# PIC32MK0128MCA032 device description
Architecture: MIPS; Family: PIC32MK; Series: PIC32MK
Registers are 32-bit, read-write, no defined reset value unless marked. A register's access mark holds for its fields unless they carry their own. Offsets are from the block's base; [hi:lo] are bit positions; lines under a group give offsets from that group; {n}, {i} and the like mark numbered series.

## INT
Instances: INT 0x1f810000 in periph_pb1_fast
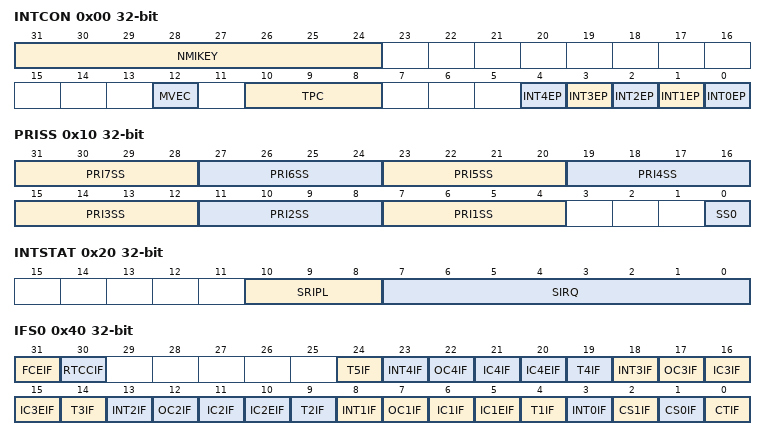
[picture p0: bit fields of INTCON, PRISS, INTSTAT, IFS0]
0x00 INTCON — Interrupt Control Register
  [31:24] NMIKEY
  [12] MVEC — Multi Vector Configuration bit
    1=Interrupt controller configured for multi vectored mode; 0=Interrupt controller configured for single vectored mode
  [10:8] TPC — Interrupt Proximity Timer Control bits
    {v}=Interrupts of group priority {v} or lower start the Interrupt Proximity timer (v=2..7); 1=Interrupts of group priority 1 start the Interrupt Proximity timer; 0=Disables Interrupt Proximity timer
  [n] INT{n}EP (n=0..4) — External Interrupt {n} Edge
    1=Rising edge; 0=Falling edge
0x10 PRISS — Priority Shadow Select Register
  [4n+3:4n] PRI{n}SS (n=1..7) — Interrupt with Priority Level {n} Shadow Set bits
    {v}=Interrupt with a priority level of {n} uses Shadow Set {v} (v=1..7); 0=Interrupt with a priority level of {n} uses Shadow Set 0 (default)
  [0] SS0 — Single Vector Shadow Register Set bit
    1=Single vector is presented with a shadow set; 0=Single vector is not presented with a shadow set
0x20 INTSTAT ro
  [10:8] SRIPL, [7:0] SIRQ
0x30 IPTMR
0x40 IFS0
  [31] FCEIF, [30] RTCCIF, [5n-1] T{n}IF (n=1..5), [5n+3] INT{n}IF (n=0..4), [5n+2] OC{n}IF (n=1..4), [5n+1] IC{n}IF (n=1..4), [5n] IC{n}EIF (n=1..4), [2] CS1IF, [1] CS0IF, [0] CTIF
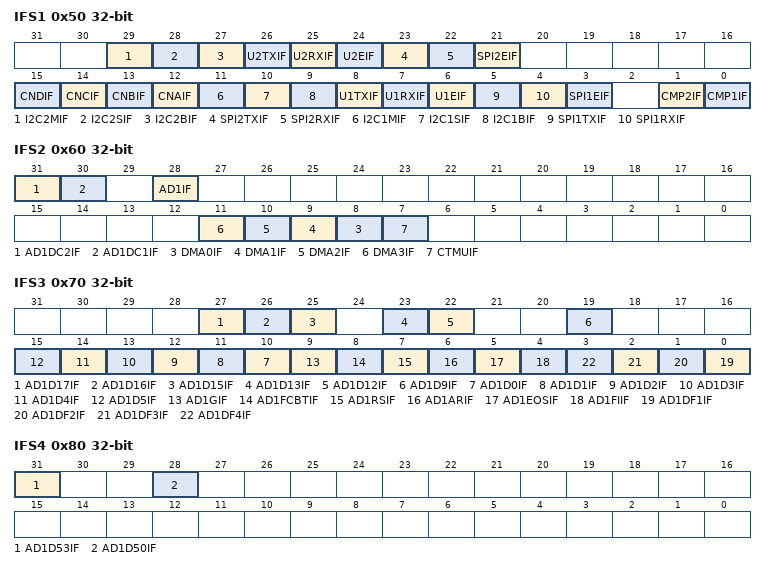
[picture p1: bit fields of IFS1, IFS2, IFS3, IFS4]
0x50 IFS1
  [29] I2C2MIF, [28] I2C2SIF, [27] I2C2BIF, [26] U2TXIF, [25] U2RXIF, [24] U2EIF, [23] SPI2TXIF, [22] SPI2RXIF, [21] SPI2EIF, [15] CNDIF, [14] CNCIF, [13] CNBIF, [12] CNAIF, [11] I2C1MIF, [10] I2C1SIF, [9] I2C1BIF, [8] U1TXIF, [7] U1RXIF, [6] U1EIF, [5] SPI1TXIF, [4] SPI1RXIF, [3] SPI1EIF, [1] CMP2IF, [0] CMP1IF
0x60 IFS2
  [31] AD1DC2IF, [30] AD1DC1IF, [28] AD1IF, [n+8] DMA{n}IF (n=0..3), [7] CTMUIF
0x70 IFS3
  [27] AD1D17IF, [26] AD1D16IF, [25] AD1D15IF, [23] AD1D13IF, [22] AD1D12IF, [19] AD1D9IF, [n+10] AD1D{n}IF (n=0..5), [9] AD1GIF, [8] AD1FCBTIF, [7] AD1RSIF, [6] AD1ARIF, [5] AD1EOSIF, [4] AD1FIIF, [n-1] AD1DF{n}IF (n=1..4)
0x80 IFS4
  [31] AD1D53IF, [28] AD1D50IF
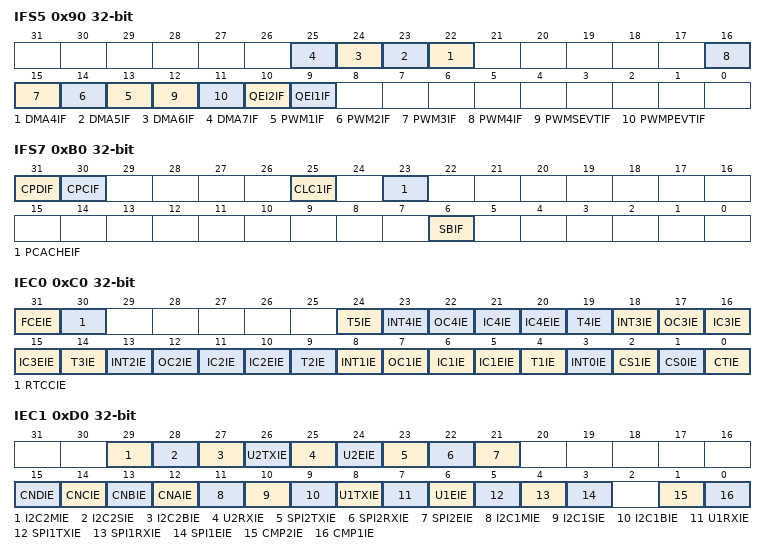
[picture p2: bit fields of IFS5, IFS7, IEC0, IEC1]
0x90 IFS5
  [n+18] DMA{n}IF (n=4..7), [n+12] PWM{n}IF (n=1..4), [12] PWMSEVTIF, [11] PWMPEVTIF, [10] QEI2IF, [9] QEI1IF
0xB0 IFS7
  [31] CPDIF
  [30] CPCIF
  [25] CLC1IF
  [23] PCACHEIF — PCACHE Interrupt Flag
  [6] SBIF
0xC0 IEC0
  [31] FCEIE, [30] RTCCIE, [5n-1] T{n}IE (n=1..5), [5n+3] INT{n}IE (n=0..4), [5n+2] OC{n}IE (n=1..4), [5n+1] IC{n}IE (n=1..4), [5n] IC{n}EIE (n=1..4), [2] CS1IE, [1] CS0IE, [0] CTIE
0xD0 IEC1
  [29] I2C2MIE, [28] I2C2SIE, [27] I2C2BIE, [26] U2TXIE, [25] U2RXIE, [24] U2EIE, [23] SPI2TXIE, [22] SPI2RXIE, [21] SPI2EIE, [15] CNDIE, [14] CNCIE, [13] CNBIE, [12] CNAIE, [11] I2C1MIE, [10] I2C1SIE, [9] I2C1BIE, [8] U1TXIE, [7] U1RXIE, [6] U1EIE, [5] SPI1TXIE, [4] SPI1RXIE, [3] SPI1EIE, [1] CMP2IE, [0] CMP1IE
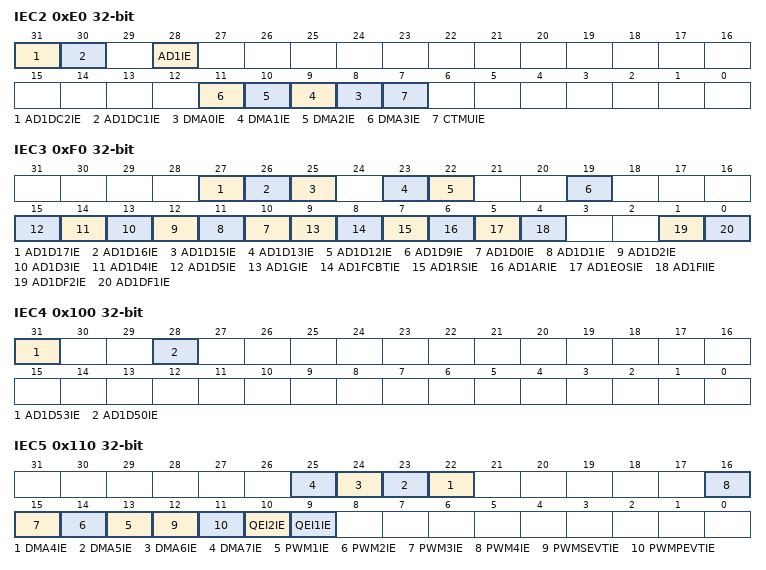
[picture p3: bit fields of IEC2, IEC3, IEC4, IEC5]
0xE0 IEC2
  [31] AD1DC2IE, [30] AD1DC1IE, [28] AD1IE, [n+8] DMA{n}IE (n=0..3), [7] CTMUIE
0xF0 IEC3
  [27] AD1D17IE, [26] AD1D16IE, [25] AD1D15IE, [23] AD1D13IE, [22] AD1D12IE, [19] AD1D9IE, [n+10] AD1D{n}IE (n=0..5), [9] AD1GIE, [8] AD1FCBTIE, [7] AD1RSIE, [6] AD1ARIE, [5] AD1EOSIE, [4] AD1FIIE, [1] AD1DF2IE, [0] AD1DF1IE
0x100 IEC4
  [31] AD1D53IE, [28] AD1D50IE
0x110 IEC5
  [n+18] DMA{n}IE (n=4..7), [n+12] PWM{n}IE (n=1..4), [12] PWMSEVTIE, [11] PWMPEVTIE, [10] QEI2IE, [9] QEI1IE
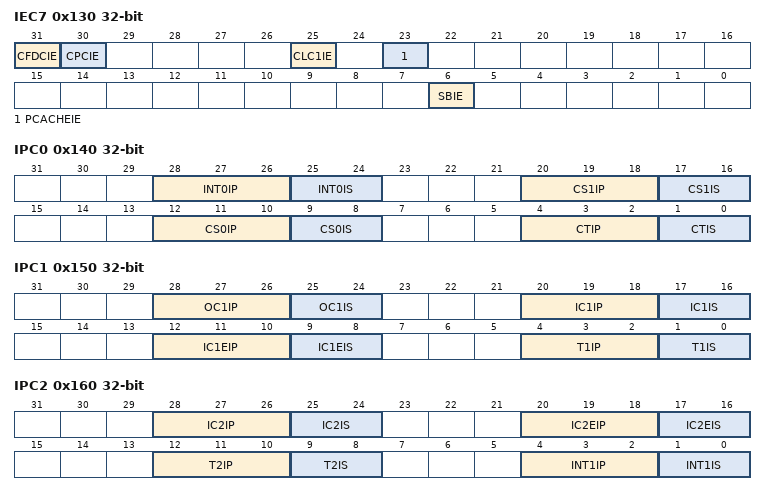
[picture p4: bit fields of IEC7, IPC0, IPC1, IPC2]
0x130 IEC7
  [31] CFDCIE
  [30] CPCIE
  [25] CLC1IE
  [23] PCACHEIE — PCACHE Interrupt Enable
  [6] SBIE
0x140 IPC0
  [28:26] INT0IP, [25:24] INT0IS, [20:18] CS1IP, [17:16] CS1IS, [12:10] CS0IP, [9:8] CS0IS, [4:2] CTIP, [1:0] CTIS
0x150 IPC1
  [28:26] OC1IP, [25:24] OC1IS, [20:18] IC1IP, [17:16] IC1IS, [12:10] IC1EIP, [9:8] IC1EIS, [4:2] T1IP, [1:0] T1IS
0x160 IPC2
  [28:26] IC2IP, [25:24] IC2IS, [20:18] IC2EIP, [17:16] IC2EIS, [12:10] T2IP, [9:8] T2IS, [4:2] INT1IP, [1:0] INT1IS
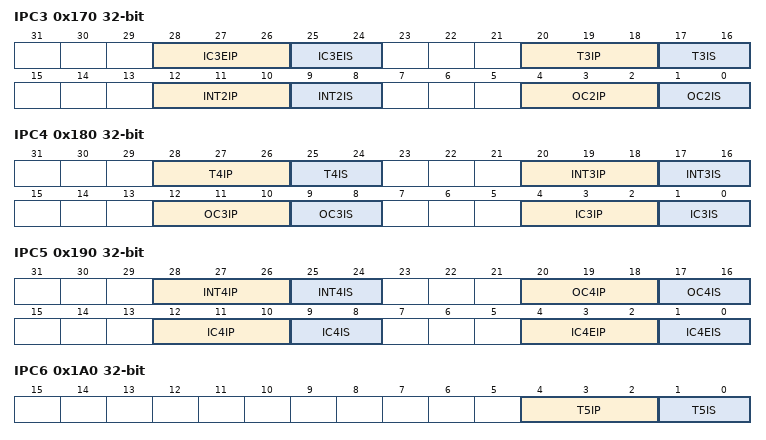
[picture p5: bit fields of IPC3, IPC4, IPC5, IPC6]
0x170 IPC3
  [28:26] IC3EIP, [25:24] IC3EIS, [20:18] T3IP, [17:16] T3IS, [12:10] INT2IP, [9:8] INT2IS, [4:2] OC2IP, [1:0] OC2IS
0x180 IPC4
  [28:26] T4IP, [25:24] T4IS, [20:18] INT3IP, [17:16] INT3IS, [12:10] OC3IP, [9:8] OC3IS, [4:2] IC3IP, [1:0] IC3IS
0x190 IPC5
  [28:26] INT4IP, [25:24] INT4IS, [20:18] OC4IP, [17:16] OC4IS, [12:10] IC4IP, [9:8] IC4IS, [4:2] IC4EIP, [1:0] IC4EIS
0x1A0 IPC6
  [4:2] T5IP, [1:0] T5IS
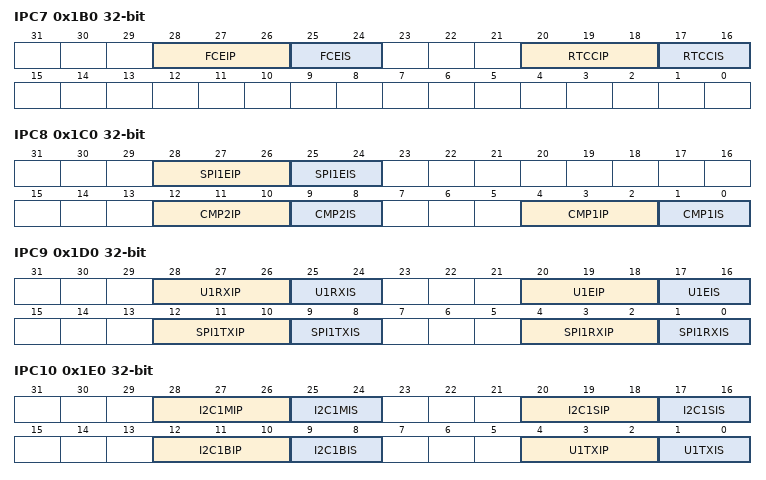
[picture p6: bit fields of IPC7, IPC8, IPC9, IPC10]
0x1B0 IPC7
  [28:26] FCEIP, [25:24] FCEIS, [20:18] RTCCIP, [17:16] RTCCIS
0x1C0 IPC8
  [28:26] SPI1EIP, [25:24] SPI1EIS, [12:10] CMP2IP, [9:8] CMP2IS, [4:2] CMP1IP, [1:0] CMP1IS
0x1D0 IPC9
  [28:26] U1RXIP, [25:24] U1RXIS, [20:18] U1EIP, [17:16] U1EIS, [12:10] SPI1TXIP, [9:8] SPI1TXIS, [4:2] SPI1RXIP, [1:0] SPI1RXIS
0x1E0 IPC10
  [28:26] I2C1MIP, [25:24] I2C1MIS, [20:18] I2C1SIP, [17:16] I2C1SIS, [12:10] I2C1BIP, [9:8] I2C1BIS, [4:2] U1TXIP, [1:0] U1TXIS
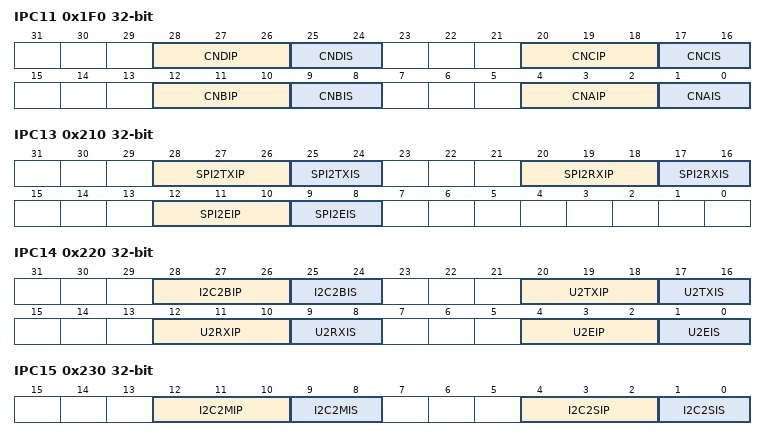
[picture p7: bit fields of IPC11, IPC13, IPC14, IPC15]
0x1F0 IPC11
  [28:26] CNDIP, [25:24] CNDIS, [20:18] CNCIP, [17:16] CNCIS, [12:10] CNBIP, [9:8] CNBIS, [4:2] CNAIP, [1:0] CNAIS
0x210 IPC13
  [28:26] SPI2TXIP, [25:24] SPI2TXIS, [20:18] SPI2RXIP, [17:16] SPI2RXIS, [12:10] SPI2EIP, [9:8] SPI2EIS
0x220 IPC14
  [28:26] I2C2BIP, [25:24] I2C2BIS, [20:18] U2TXIP, [17:16] U2TXIS, [12:10] U2RXIP, [9:8] U2RXIS, [4:2] U2EIP, [1:0] U2EIS
0x230 IPC15
  [12:10] I2C2MIP, [9:8] I2C2MIS, [4:2] I2C2SIP, [1:0] I2C2SIS
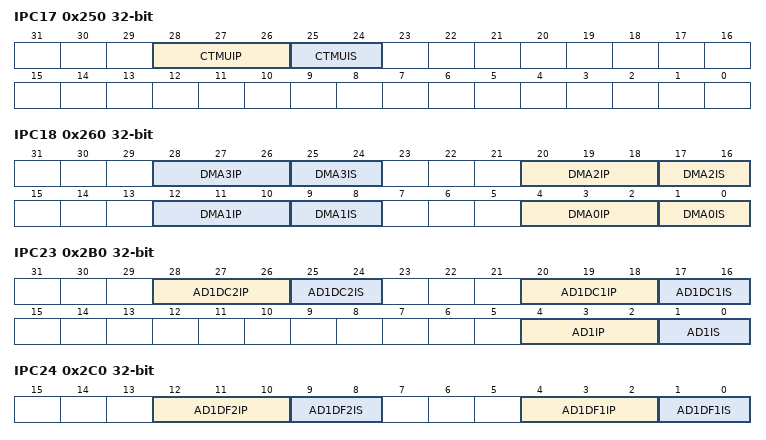
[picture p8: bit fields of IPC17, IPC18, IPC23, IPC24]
0x250 IPC17
  [28:26] CTMUIP, [25:24] CTMUIS
0x260 IPC18
  [8n+4:8n+2] DMA{n}IP (n=0..3), [8n+1:8n] DMA{n}IS (n=0..3)
0x2B0 IPC23
  [28:26] AD1DC2IP, [25:24] AD1DC2IS, [20:18] AD1DC1IP, [17:16] AD1DC1IS, [4:2] AD1IP, [1:0] AD1IS
0x2C0 IPC24
  [12:10] AD1DF2IP, [9:8] AD1DF2IS, [4:2] AD1DF1IP, [1:0] AD1DF1IS
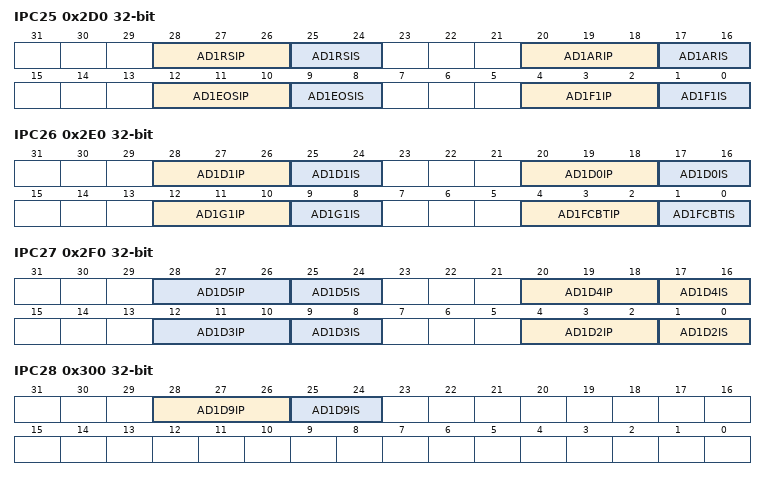
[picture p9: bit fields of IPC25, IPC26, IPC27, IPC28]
0x2D0 IPC25
  [28:26] AD1RSIP, [25:24] AD1RSIS, [20:18] AD1ARIP, [17:16] AD1ARIS, [12:10] AD1EOSIP, [9:8] AD1EOSIS, [4:2] AD1F1IP, [1:0] AD1F1IS
0x2E0 IPC26
  [28:26] AD1D1IP, [25:24] AD1D1IS, [20:18] AD1D0IP, [17:16] AD1D0IS, [12:10] AD1G1IP, [9:8] AD1G1IS, [4:2] AD1FCBTIP, [1:0] AD1FCBTIS
0x2F0 IPC27
  [8n-12:8n-14] AD1D{n}IP (n=2..5), [8n-15:8n-16] AD1D{n}IS (n=2..5)
0x300 IPC28
  [28:26] AD1D9IP, [25:24] AD1D9IS
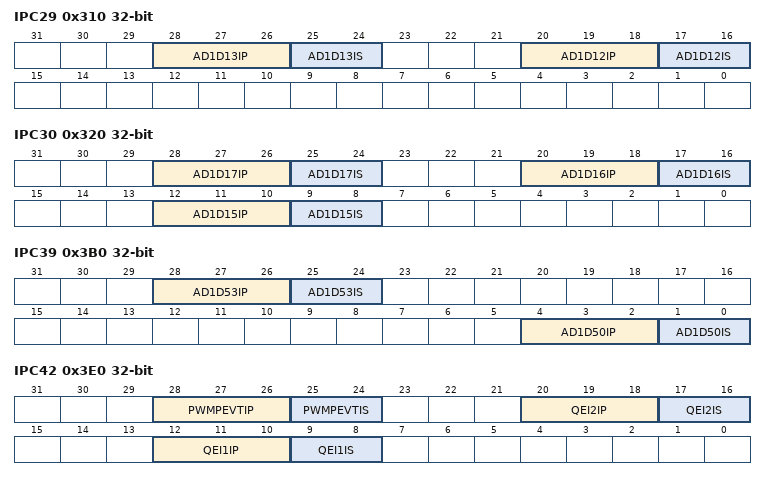
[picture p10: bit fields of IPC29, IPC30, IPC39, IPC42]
0x310 IPC29
  [28:26] AD1D13IP, [25:24] AD1D13IS, [20:18] AD1D12IP, [17:16] AD1D12IS
0x320 IPC30
  [28:26] AD1D17IP, [25:24] AD1D17IS, [20:18] AD1D16IP, [17:16] AD1D16IS, [12:10] AD1D15IP, [9:8] AD1D15IS
0x3B0 IPC39
  [28:26] AD1D53IP, [25:24] AD1D53IS, [4:2] AD1D50IP, [1:0] AD1D50IS
0x3C0 IPC40
0x3E0 IPC42
  [28:26] PWMPEVTIP, [25:24] PWMPEVTIS, [20:18] QEI2IP, [17:16] QEI2IS, [12:10] QEI1IP, [9:8] QEI1IS
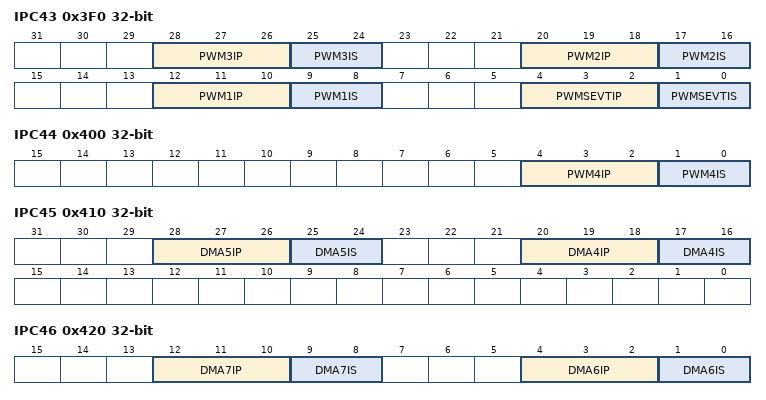
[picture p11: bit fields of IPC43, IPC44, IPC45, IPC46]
0x3F0 IPC43
  [28:26] PWM3IP, [25:24] PWM3IS, [20:18] PWM2IP, [17:16] PWM2IS, [12:10] PWM1IP, [9:8] PWM1IS, [4:2] PWMSEVTIP, [1:0] PWMSEVTIS
0x400 IPC44 ro
  [4:2] PWM4IP, [1:0] PWM4IS
0x410 IPC45
  [28:26] DMA5IP, [25:24] DMA5IS, [20:18] DMA4IP, [17:16] DMA4IS
0x420 IPC46
  [12:10] DMA7IP, [9:8] DMA7IS, [4:2] DMA6IP, [1:0] DMA6IS
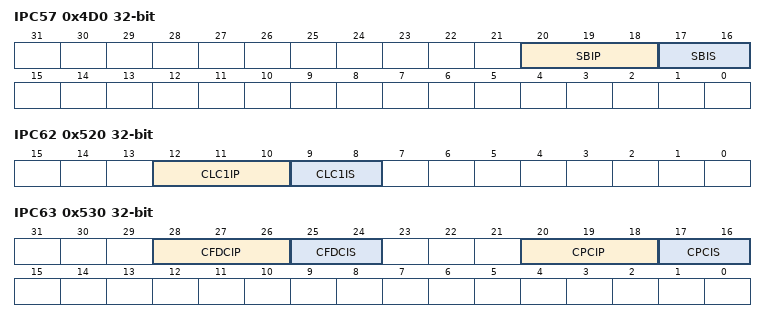
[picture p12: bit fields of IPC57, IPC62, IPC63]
0x4D0 IPC57
  [20:18] SBIP, [17:16] SBIS
0x520 IPC62
  [12:10] CLC1IP, [9:8] CLC1IS
0x530 IPC63
  [28:26] CFDCIP, [25:24] CFDCIS, [20:18] CPCIP, [17:16] CPCIS
{0x540+4i} OFF{i:03} (i=0..24)
  [17:1] VOFF
{0x540+4i} OFF{i:03} (i=30..33)
  [17:1] VOFF
{0x540+4i} OFF{i:03} (i=35..47)
  [17:1] VOFF
{0x540+4i} OFF{i:03} (i=53..61)
  [17:1] VOFF
{0x540+4i} OFF{i:03} (i=71..75)
  [17:1] VOFF
0x6B0 OFF092
  [17:1] VOFF
{0x540+4i} OFF{i:03} (i=94..97)
  [17:1] VOFF
{0x540+4i} OFF{i} (i=100..111)
  [17:1] VOFF
0x70C OFF115
  [17:1] VOFF
0x718 OFF118
  [17:1] VOFF
0x71C OFF119
  [17:1] VOFF
{0x540+4i} OFF{i} (i=121..123)
  [17:1] VOFF
0x7BC OFF159
  [17:1] VOFF
0x7C0 OFF160
  [17:1] VOFF
{0x540+4i} OFF{i} (i=169..176)
  [17:1] VOFF
{0x540+4i} OFF{i} (i=182..185)
  [17:1] VOFF
0x8D8 OFF230
  [17:1] VOFF
0x91C OFF247
  [17:1] VOFF
0x924 OFF249
  [17:1] VOFF
0x938 OFF254
  [17:1] VOFF
0x93C OFF255
  [17:1] VOFF
